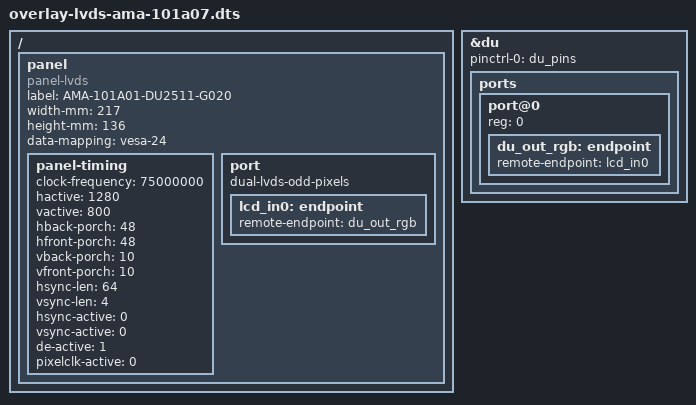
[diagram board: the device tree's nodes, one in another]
/*
 * Copyright (C) 2022 Avnet Embedded GmbH
 *
 * This program is free software; you can redistribute it and/or
 * modify it under the terms of the GNU General Public License as
 * published by the Free Software Foundation version 2.
 *
 * This program is distributed "as is" WITHOUT ANY WARRANTY of any
 * kind, whether express or implied; without even the implied warranty
 * of MERCHANTABILITY or FITNESS FOR A PARTICULAR PURPOSE.  See the
 * GNU General Public License for more details.
 */

/dts-v1/;
/plugin/;

/ {
       fragment@4000 {
               target-path = "/";
               __overlay__ {
                       panel {
                                compatible = "panel-lvds";
                		label = "AMA-101A01-DU2511-G020";
                		width-mm = <217>;
                		height-mm = <136>;
                		data-mapping = "vesa-24";
                		status = "okay";

                		panel-timing {
                		    clock-frequency = <75000000>;
                		    hactive = <1280>;
                		    vactive = <800>;
                		    hback-porch = <48>;
                		    hfront-porch = <48>;
                		    vback-porch = <10>;
                		    vfront-porch = <10>;
                		    hsync-len = <64>;
                		    vsync-len = <4>;
                		    hsync-active = <0>;
                		    vsync-active = <0>;
                		    de-active = <1>;
                		    pixelclk-active = <0>;
                		};

                		port {
                		    dual-lvds-odd-pixels;
                		    lcd_in0: endpoint {
                		    	remote-endpoint = <&du_out_rgb>;
                		    };
                		};

                       };
               };
       };

	fragment@4001 {
                target = <&du>;
                __overlay__ {
                        pinctrl-0 = <&du_pins>;
                        pinctrl-names = "default";
                        status = "okay";

                        ports {
                                port@0 {
                                        reg = <0>;
                                        du_out_rgb: endpoint {
                                                remote-endpoint = <&lcd_in0>;
                                        };
                                };
                        };
                };
        };
};

